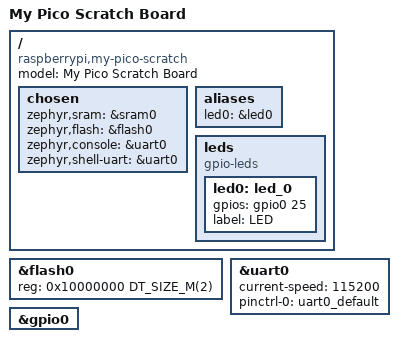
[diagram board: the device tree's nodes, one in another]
/dts-v1/;

#include <raspberrypi/rpi_pico/rp2040.dtsi>
#include "my_pico_scratch-pinctrl.dtsi"
#include <zephyr/dt-bindings/gpio/gpio.h>

/ {
	model = "My Pico Scratch Board";
	compatible = "raspberrypi,my-pico-scratch";

	chosen {
		zephyr,sram = &sram0;
		zephyr,flash = &flash0;
		zephyr,console = &uart0;
		zephyr,shell-uart = &uart0;
	};

	aliases {
		led0 = &led0;
	};

	leds {
		compatible = "gpio-leds";
		led0: led_0 {
			gpios = <&gpio0 25 GPIO_ACTIVE_HIGH>;
			label = "LED";
		};
	};
};

&flash0 {
	reg = <0x10000000 DT_SIZE_M(2)>;
};

&uart0 {
	status = "okay";
	current-speed = <115200>;
	pinctrl-0 = <&uart0_default>;
	pinctrl-names = "default";
};

&gpio0 {
	status = "okay";
};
